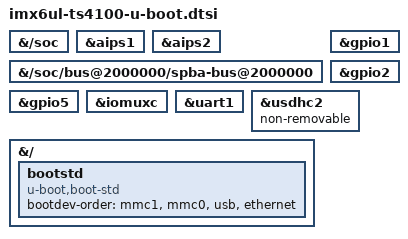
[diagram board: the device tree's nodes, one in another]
// SPDX-License-Identifier: GPL-2.0+

&{/soc} {
	bootph-pre-ram;
};

&aips1 {
	bootph-pre-ram;
};

&aips2 {
	bootph-pre-ram;
};

&{/soc/bus@2000000/spba-bus@2000000} {
	bootph-pre-ram;
};

&gpio1 {
	bootph-pre-ram;
};

&gpio2 {
	bootph-pre-ram;
};

&gpio5 {
	bootph-pre-ram;
};

&iomuxc {
	bootph-pre-ram;
};

&uart1 {
	bootph-pre-ram;
};

&usdhc2 {
	bootph-pre-ram;
	/* U-Boot needs the eMMC to be available even without card-detect. */
	non-removable;
};

&{/} {
	bootstd {
		bootph-verify;
		compatible = "u-boot,boot-std";
		bootdev-order = "mmc1", "mmc0", "usb", "ethernet";
	};
};
